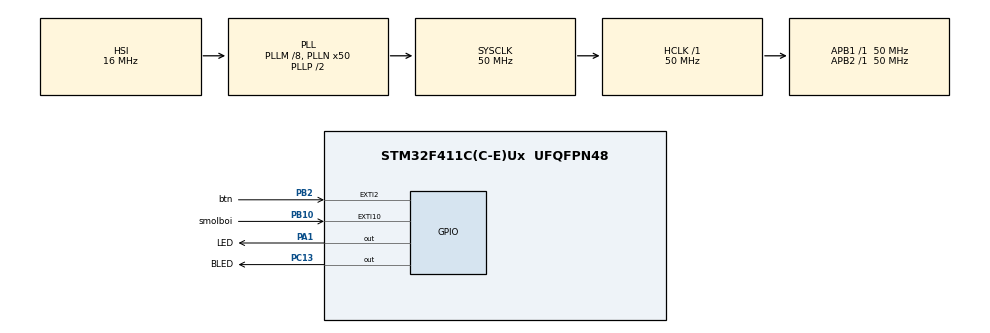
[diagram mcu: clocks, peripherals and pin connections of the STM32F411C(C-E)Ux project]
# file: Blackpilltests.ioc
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Mcu.Family=STM32F4
Mcu.Name=STM32F411C(C-E)Ux
Mcu.Package=UFQFPN48
NVIC.EXTI15_10_IRQn=true\:0\:0\:false\:false\:true\:true\:true\:true
NVIC.EXTI2_IRQn=true\:0\:0\:false\:false\:true\:true\:true\:true
NVIC.PriorityGroup=NVIC_PRIORITYGROUP_4
PA1.GPIO_Label=LED
PA1.Signal=GPIO_Output
PB10.GPIO_Label=smolboi
PB10.GPIO_ModeDefaultEXTI=GPIO_MODE_IT_FALLING
PB10.Signal=GPXTI10
PB2.GPIO_Label=btn
PB2.GPIO_ModeDefaultEXTI=GPIO_MODE_IT_FALLING
PB2.Signal=GPXTI2
PC13-ANTI_TAMP.GPIO_Label=BLED
PC13-ANTI_TAMP.Signal=GPIO_Output
ProjectManager.HeapSize=0x200
ProjectManager.StackSize=0x400
ProjectManager.TargetToolchain=STM32CubeIDE
RCC.48MHZClocksFreq_Value=25000000
RCC.AHBFreq_Value=50000000
RCC.APB1Freq_Value=50000000
RCC.APB1TimFreq_Value=50000000
RCC.APB2Freq_Value=50000000
RCC.APB2TimFreq_Value=50000000
RCC.CortexFreq_Value=50000000
RCC.HCLKFreq_Value=50000000
RCC.HSE_VALUE=25000000
RCC.HSI_VALUE=16000000
RCC.LSE_VALUE=32768
RCC.PLLM=8
RCC.PLLN=50
RCC.SYSCLKFreq_VALUE=50000000
RCC.SYSCLKSource=RCC_SYSCLKSOURCE_PLLCLK
RCC.VCOOutputFreq_Value=100000000
board=custom

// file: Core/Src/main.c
/* USER CODE BEGIN Header */
/**
  ******************************************************************************
  * @file           : main.c
  * @brief          : Main program body
  ******************************************************************************
  * @attention
  *
  * Copyright (c) 2022 STMicroelectronics.
  * All rights reserved.
  *
  * This software is licensed under terms that can be found in the LICENSE file
  * in the root directory of this software component.
  * If no LICENSE file comes with this software, it is provided AS-IS.
  *
  ******************************************************************************
  */
/* USER CODE END Header */
#include "main.h"

/* USER CODE BEGIN PV */

uint32_t previousMillis = 0;
uint32_t currentMillis = 0;
uint32_t counterOutside = 0; //For testing only
uint32_t counterInside = 0; //For testing only

/* USER CODE END PV */

void SystemClock_Config(void);
static void MX_GPIO_Init(void);

int main(void)
{

  /* MCU Configuration--------------------------------------------------------*/

  /* Reset of all peripherals, Initializes the Flash interface and the Systick. */
  HAL_Init();

  /* Configure the system clock */
  SystemClock_Config();

  /* Initialize all configured peripherals */
  MX_GPIO_Init();

  /* Infinite loop */
  /* USER CODE BEGIN WHILE */
  while (1)
  {
//	  HAL_GPIO_WritePin(LED_GPIO_Port, LED_Pin, 1);

    /* USER CODE END WHILE */

  }
}

void SystemClock_Config(void)
{
  RCC_OscInitTypeDef RCC_OscInitStruct = {0};
  RCC_ClkInitTypeDef RCC_ClkInitStruct = {0};

  /** Configure the main internal regulator output voltage
  */
  __HAL_RCC_PWR_CLK_ENABLE();
  __HAL_PWR_VOLTAGESCALING_CONFIG(PWR_REGULATOR_VOLTAGE_SCALE1);

  /** Initializes the RCC Oscillators according to the specified parameters
  * in the RCC_OscInitTypeDef structure.
  */
  RCC_OscInitStruct.OscillatorType = RCC_OSCILLATORTYPE_HSI;
  RCC_OscInitStruct.HSIState = RCC_HSI_ON;
  RCC_OscInitStruct.HSICalibrationValue = RCC_HSICALIBRATION_DEFAULT;
  RCC_OscInitStruct.PLL.PLLState = RCC_PLL_ON;
  RCC_OscInitStruct.PLL.PLLSource = RCC_PLLSOURCE_HSI;
  RCC_OscInitStruct.PLL.PLLM = 8;
  RCC_OscInitStruct.PLL.PLLN = 50;
  RCC_OscInitStruct.PLL.PLLP = RCC_PLLP_DIV2;
  RCC_OscInitStruct.PLL.PLLQ = 4;
  if (HAL_RCC_OscConfig(&RCC_OscInitStruct) != HAL_OK)
  {
    Error_Handler();
  }

  /** Initializes the CPU, AHB and APB buses clocks
  */
  RCC_ClkInitStruct.ClockType = RCC_CLOCKTYPE_HCLK|RCC_CLOCKTYPE_SYSCLK
                              |RCC_CLOCKTYPE_PCLK1|RCC_CLOCKTYPE_PCLK2;
  RCC_ClkInitStruct.SYSCLKSource = RCC_SYSCLKSOURCE_PLLCLK;
  RCC_ClkInitStruct.AHBCLKDivider = RCC_SYSCLK_DIV1;
  RCC_ClkInitStruct.APB1CLKDivider = RCC_HCLK_DIV1;
  RCC_ClkInitStruct.APB2CLKDivider = RCC_HCLK_DIV1;

  if (HAL_RCC_ClockConfig(&RCC_ClkInitStruct, FLASH_LATENCY_1) != HAL_OK)
  {
    Error_Handler();
  }
}

static void MX_GPIO_Init(void)
{
  GPIO_InitTypeDef GPIO_InitStruct = {0};

  /* GPIO Ports Clock Enable */
  __HAL_RCC_GPIOC_CLK_ENABLE();
  __HAL_RCC_GPIOA_CLK_ENABLE();
  __HAL_RCC_GPIOB_CLK_ENABLE();

  /*Configure GPIO pin Output Level */
  HAL_GPIO_WritePin(BLED_GPIO_Port, BLED_Pin, GPIO_PIN_RESET);

  /*Configure GPIO pin Output Level */
  HAL_GPIO_WritePin(LED_GPIO_Port, LED_Pin, GPIO_PIN_RESET);

  /*Configure GPIO pin : BLED_Pin */
  GPIO_InitStruct.Pin = BLED_Pin;
  GPIO_InitStruct.Mode = GPIO_MODE_OUTPUT_PP;
  GPIO_InitStruct.Pull = GPIO_NOPULL;
  GPIO_InitStruct.Speed = GPIO_SPEED_FREQ_LOW;
  HAL_GPIO_Init(BLED_GPIO_Port, &GPIO_InitStruct);

  /*Configure GPIO pin : LED_Pin */
  GPIO_InitStruct.Pin = LED_Pin;
  GPIO_InitStruct.Mode = GPIO_MODE_OUTPUT_PP;
  GPIO_InitStruct.Pull = GPIO_NOPULL;
  GPIO_InitStruct.Speed = GPIO_SPEED_FREQ_LOW;
  HAL_GPIO_Init(LED_GPIO_Port, &GPIO_InitStruct);

  /*Configure GPIO pins : btn_Pin smolboi_Pin */
  GPIO_InitStruct.Pin = btn_Pin|smolboi_Pin;
  GPIO_InitStruct.Mode = GPIO_MODE_IT_FALLING;
  GPIO_InitStruct.Pull = GPIO_NOPULL;
  HAL_GPIO_Init(GPIOB, &GPIO_InitStruct);

  /* EXTI interrupt init*/
  HAL_NVIC_SetPriority(EXTI2_IRQn, 0, 0);
  HAL_NVIC_EnableIRQ(EXTI2_IRQn);

  HAL_NVIC_SetPriority(EXTI15_10_IRQn, 0, 0);
  HAL_NVIC_EnableIRQ(EXTI15_10_IRQn);

}

/* USER CODE BEGIN 4 */

void HAL_GPIO_EXTI_Callback(uint16_t GPIO_Pin)
{
//  counterOutside++; //For testing only
//  currentMillis = HAL_GetTick();
  if (GPIO_Pin == smolboi_Pin )//&& (currentMillis - previousMillis > 10))
  {
//    counterInside++; //For testing only
    HAL_GPIO_TogglePin(LED_GPIO_Port, LED_Pin);
//    previousMillis = currentMillis;
  }else {
	  __NOP ();
  }
}

/* USER CODE END 4 */

void Error_Handler(void)
{
  __disable_irq();
  while (1)
  {
  }
}
